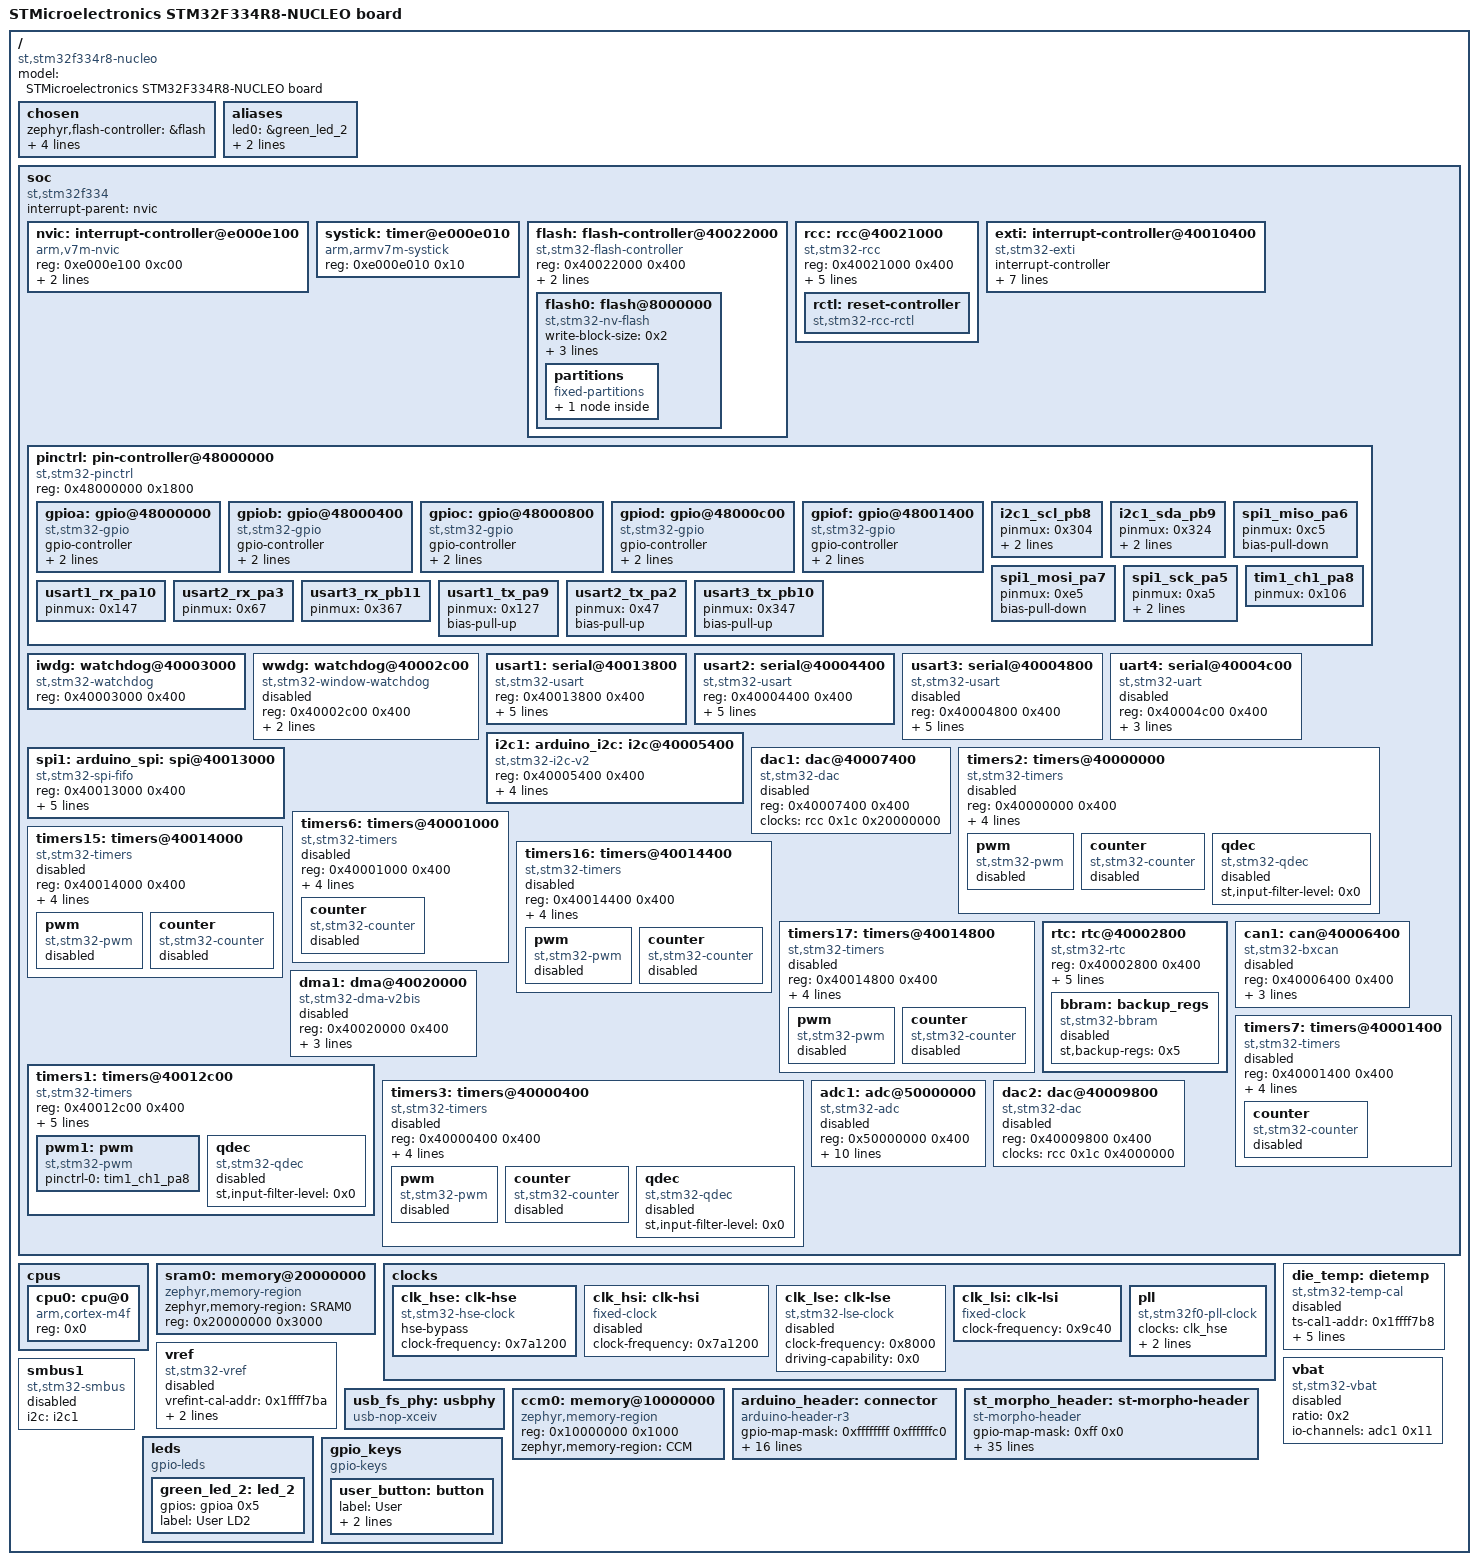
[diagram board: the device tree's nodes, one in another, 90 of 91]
/dts-v1/;

/* node '/' defined in zephyr/dts/common/skeleton.dtsi:9 */
/ {
	#address-cells = < 0x1 >;                              /* in zephyr/dts/common/skeleton.dtsi:10 */
	#size-cells = < 0x1 >;                                 /* in zephyr/dts/common/skeleton.dtsi:11 */
	model = "STMicroelectronics STM32F334R8-NUCLEO board"; /* in zephyr/boards/st/nucleo_f334r8/nucleo_f334r8.dts:15 */
	compatible = "st,stm32f334r8-nucleo";                  /* in zephyr/boards/st/nucleo_f334r8/nucleo_f334r8.dts:16 */

	/* node '/chosen' defined in zephyr/dts/common/skeleton.dtsi:13 */
	chosen {
		zephyr,flash-controller = &flash; /* in zephyr/dts/arm/st/f3/stm32f3.dtsi:24 */
		zephyr,console = &usart2;         /* in zephyr/boards/st/nucleo_f334r8/nucleo_f334r8.dts:19 */
		zephyr,shell-uart = &usart2;      /* in zephyr/boards/st/nucleo_f334r8/nucleo_f334r8.dts:20 */
		zephyr,sram = &sram0;             /* in zephyr/boards/st/nucleo_f334r8/nucleo_f334r8.dts:21 */
		zephyr,flash = &flash0;           /* in zephyr/boards/st/nucleo_f334r8/nucleo_f334r8.dts:22 */
	};

	/* node '/aliases' defined in zephyr/dts/common/skeleton.dtsi:15 */
	aliases {
		led0 = &green_led_2; /* in zephyr/boards/st/nucleo_f334r8/nucleo_f334r8.dts:45 */
		sw0 = &user_button;  /* in zephyr/boards/st/nucleo_f334r8/nucleo_f334r8.dts:46 */
		watchdog0 = &iwdg;   /* in zephyr/boards/st/nucleo_f334r8/nucleo_f334r8.dts:47 */
	};

	/* node '/soc' defined in zephyr/dts/arm/armv7-m.dtsi:6 */
	soc {
		#address-cells = < 0x1 >;     /* in zephyr/dts/arm/armv7-m.dtsi:7 */
		#size-cells = < 0x1 >;        /* in zephyr/dts/arm/armv7-m.dtsi:8 */
		interrupt-parent = < &nvic >; /* in zephyr/dts/arm/armv7-m.dtsi:10 */
		ranges;                       /* in zephyr/dts/arm/armv7-m.dtsi:11 */
		compatible = "st,stm32f334",
		             "st,stm32f3",
		             "simple-bus";    /* in zephyr/dts/arm/st/f3/stm32f334.dtsi:13 */

		/* node '/soc/interrupt-controller@e000e100' defined in zephyr/dts/arm/armv7-m.dtsi:13 */
		nvic: interrupt-controller@e000e100 {
			#address-cells = < 0x1 >;            /* in zephyr/dts/arm/armv7-m.dtsi:14 */
			compatible = "arm,v7m-nvic";         /* in zephyr/dts/arm/armv7-m.dtsi:15 */
			reg = < 0xe000e100 0xc00 >;          /* in zephyr/dts/arm/armv7-m.dtsi:16 */
			interrupt-controller;                /* in zephyr/dts/arm/armv7-m.dtsi:17 */
			#interrupt-cells = < 0x2 >;          /* in zephyr/dts/arm/armv7-m.dtsi:18 */
			arm,num-irq-priority-bits = < 0x4 >; /* in zephyr/dts/arm/st/f3/stm32f3.dtsi:456 */
			phandle = < 0x1 >;                   /* in zephyr/dts/arm/armv7-m.dtsi:10 */
		};

		/* node '/soc/timer@e000e010' defined in zephyr/dts/arm/armv7-m.dtsi:21 */
		systick: timer@e000e010 {
			compatible = "arm,armv7m-systick"; /* in zephyr/dts/arm/armv7-m.dtsi:22 */
			reg = < 0xe000e010 0x10 >;         /* in zephyr/dts/arm/armv7-m.dtsi:23 */
		};

		/* node '/soc/flash-controller@40022000' defined in zephyr/dts/arm/st/f3/stm32f3.dtsi:80 */
		flash: flash-controller@40022000 {
			compatible = "st,stm32-flash-controller",
			             "st,stm32f1-flash-controller"; /* in zephyr/dts/arm/st/f3/stm32f3.dtsi:81 */
			reg = < 0x40022000 0x400 >;                 /* in zephyr/dts/arm/st/f3/stm32f3.dtsi:82 */
			interrupts = < 0x4 0x0 >;                   /* in zephyr/dts/arm/st/f3/stm32f3.dtsi:83 */
			clocks = < &rcc 0x14 0x10 >;                /* in zephyr/dts/arm/st/f3/stm32f3.dtsi:84 */
			#address-cells = < 0x1 >;                   /* in zephyr/dts/arm/st/f3/stm32f3.dtsi:86 */
			#size-cells = < 0x1 >;                      /* in zephyr/dts/arm/st/f3/stm32f3.dtsi:87 */

			/* node '/soc/flash-controller@40022000/flash@8000000' defined in zephyr/dts/arm/st/f3/stm32f3.dtsi:89 */
			flash0: flash@8000000 {
				compatible = "st,stm32-nv-flash",
				             "soc-nv-flash";      /* in zephyr/dts/arm/st/f3/stm32f3.dtsi:90 */
				write-block-size = < 0x2 >;       /* in zephyr/dts/arm/st/f3/stm32f3.dtsi:92 */
				erase-block-size = < 0x800 >;     /* in zephyr/dts/arm/st/f3/stm32f3.dtsi:93 */
				max-erase-time = < 0x28 >;        /* in zephyr/dts/arm/st/f3/stm32f3.dtsi:95 */
				reg = < 0x8000000 0x10000 >;      /* in zephyr/dts/arm/st/f3/stm32f334X8.dtsi:23 */

				/* node '/soc/flash-controller@40022000/flash@8000000/partitions' defined in zephyr/boards/st/nucleo_f334r8/nucleo_f334r8.dts:132 */
				partitions {
					compatible = "fixed-partitions"; /* in zephyr/boards/st/nucleo_f334r8/nucleo_f334r8.dts:133 */
					#address-cells = < 0x1 >;        /* in zephyr/boards/st/nucleo_f334r8/nucleo_f334r8.dts:134 */
					#size-cells = < 0x1 >;           /* in zephyr/boards/st/nucleo_f334r8/nucleo_f334r8.dts:135 */

					/* node '/soc/flash-controller@40022000/flash@8000000/partitions/partition@e800' defined in zephyr/boards/st/nucleo_f334r8/nucleo_f334r8.dts:138 */
					storage_partition: partition@e800 {
						label = "storage";       /* in zephyr/boards/st/nucleo_f334r8/nucleo_f334r8.dts:139 */
						reg = < 0xe800 0x1800 >; /* in zephyr/boards/st/nucleo_f334r8/nucleo_f334r8.dts:140 */
					};
				};
			};
		};

		/* node '/soc/rcc@40021000' defined in zephyr/dts/arm/st/f3/stm32f3.dtsi:99 */
		rcc: rcc@40021000 {
			compatible = "st,stm32-rcc";     /* in zephyr/dts/arm/st/f3/stm32f3.dtsi:100 */
			#clock-cells = < 0x2 >;          /* in zephyr/dts/arm/st/f3/stm32f3.dtsi:101 */
			reg = < 0x40021000 0x400 >;      /* in zephyr/dts/arm/st/f3/stm32f3.dtsi:102 */
			clocks = < &pll >;               /* in zephyr/boards/st/nucleo_f334r8/nucleo_f334r8.dts:69 */
			clock-frequency = < 0x44aa200 >; /* in zephyr/boards/st/nucleo_f334r8/nucleo_f334r8.dts:70 */
			ahb-prescaler = < 0x1 >;         /* in zephyr/boards/st/nucleo_f334r8/nucleo_f334r8.dts:71 */
			apb1-prescaler = < 0x2 >;        /* in zephyr/boards/st/nucleo_f334r8/nucleo_f334r8.dts:72 */
			apb2-prescaler = < 0x1 >;        /* in zephyr/boards/st/nucleo_f334r8/nucleo_f334r8.dts:73 */
			phandle = < 0x2 >;               /* in zephyr/dts/arm/st/f3/stm32f3.dtsi:84 */

			/* node '/soc/rcc@40021000/reset-controller' defined in zephyr/dts/arm/st/f3/stm32f3.dtsi:104 */
			rctl: reset-controller {
				compatible = "st,stm32-rcc-rctl"; /* in zephyr/dts/arm/st/f3/stm32f3.dtsi:105 */
				#reset-cells = < 0x1 >;           /* in zephyr/dts/arm/st/f3/stm32f3.dtsi:106 */
				phandle = < 0x4 >;                /* in zephyr/dts/arm/st/f3/stm32f3.dtsi:191 */
			};
		};

		/* node '/soc/interrupt-controller@40010400' defined in zephyr/dts/arm/st/f3/stm32f3.dtsi:110 */
		exti: interrupt-controller@40010400 {
			compatible = "st,stm32-exti";  /* in zephyr/dts/arm/st/f3/stm32f3.dtsi:111 */
			interrupt-controller;          /* in zephyr/dts/arm/st/f3/stm32f3.dtsi:112 */
			#interrupt-cells = < 0x1 >;    /* in zephyr/dts/arm/st/f3/stm32f3.dtsi:113 */
			#address-cells = < 0x0 >;      /* in zephyr/dts/arm/st/f3/stm32f3.dtsi:114 */
			reg = < 0x40010400 0x400 >;    /* in zephyr/dts/arm/st/f3/stm32f3.dtsi:115 */
			clocks = < &rcc 0x18 0x1 >;    /* in zephyr/dts/arm/st/f3/stm32f3.dtsi:116 */
			num-lines = < 0x20 >;          /* in zephyr/dts/arm/st/f3/stm32f3.dtsi:117 */
			interrupts = < 0x6 0x0 >,
			             < 0x7 0x0 >,
			             < 0x8 0x0 >,
			             < 0x9 0x0 >,
			             < 0xa 0x0 >,
			             < 0x17 0x0 >,
			             < 0x28 0x0 >;     /* in zephyr/dts/arm/st/f3/stm32f3.dtsi:118 */
			interrupt-names = "line0",
			                  "line1",
			                  "line2",
			                  "line3",
			                  "line4",
			                  "line5-9",
			                  "line10-15"; /* in zephyr/dts/arm/st/f3/stm32f3.dtsi:120 */
			line-ranges = < 0x0 0x1 >,
			              < 0x1 0x1 >,
			              < 0x2 0x1 >,
			              < 0x3 0x1 >,
			              < 0x4 0x1 >,
			              < 0x5 0x5 >,
			              < 0xa 0x6 >;     /* in zephyr/dts/arm/st/f3/stm32f3.dtsi:122 */
		};

		/* node '/soc/pin-controller@48000000' defined in zephyr/dts/arm/st/f3/stm32f3.dtsi:126 */
		pinctrl: pin-controller@48000000 {
			compatible = "st,stm32-pinctrl"; /* in zephyr/dts/arm/st/f3/stm32f3.dtsi:127 */
			#address-cells = < 0x1 >;        /* in zephyr/dts/arm/st/f3/stm32f3.dtsi:128 */
			#size-cells = < 0x1 >;           /* in zephyr/dts/arm/st/f3/stm32f3.dtsi:129 */
			reg = < 0x48000000 0x1800 >;     /* in zephyr/dts/arm/st/f3/stm32f3.dtsi:130 */

			/* node '/soc/pin-controller@48000000/gpio@48000000' defined in zephyr/dts/arm/st/f3/stm32f3.dtsi:132 */
			gpioa: gpio@48000000 {
				compatible = "st,stm32-gpio";   /* in zephyr/dts/arm/st/f3/stm32f3.dtsi:133 */
				gpio-controller;                /* in zephyr/dts/arm/st/f3/stm32f3.dtsi:134 */
				#gpio-cells = < 0x2 >;          /* in zephyr/dts/arm/st/f3/stm32f3.dtsi:135 */
				reg = < 0x48000000 0x400 >;     /* in zephyr/dts/arm/st/f3/stm32f3.dtsi:136 */
				clocks = < &rcc 0x14 0x20000 >; /* in zephyr/dts/arm/st/f3/stm32f3.dtsi:137 */
				phandle = < 0x15 >;             /* in zephyr/boards/st/nucleo_f334r8/arduino_r3_connector.dtsi:15 */
			};

			/* node '/soc/pin-controller@48000000/gpio@48000400' defined in zephyr/dts/arm/st/f3/stm32f3.dtsi:140 */
			gpiob: gpio@48000400 {
				compatible = "st,stm32-gpio";   /* in zephyr/dts/arm/st/f3/stm32f3.dtsi:141 */
				gpio-controller;                /* in zephyr/dts/arm/st/f3/stm32f3.dtsi:142 */
				#gpio-cells = < 0x2 >;          /* in zephyr/dts/arm/st/f3/stm32f3.dtsi:143 */
				reg = < 0x48000400 0x400 >;     /* in zephyr/dts/arm/st/f3/stm32f3.dtsi:144 */
				clocks = < &rcc 0x14 0x40000 >; /* in zephyr/dts/arm/st/f3/stm32f3.dtsi:145 */
				phandle = < 0x10 >;             /* in zephyr/boards/st/nucleo_f334r8/nucleo_f334r8.dts:106 */
			};

			/* node '/soc/pin-controller@48000000/gpio@48000800' defined in zephyr/dts/arm/st/f3/stm32f3.dtsi:148 */
			gpioc: gpio@48000800 {
				compatible = "st,stm32-gpio";   /* in zephyr/dts/arm/st/f3/stm32f3.dtsi:149 */
				gpio-controller;                /* in zephyr/dts/arm/st/f3/stm32f3.dtsi:150 */
				#gpio-cells = < 0x2 >;          /* in zephyr/dts/arm/st/f3/stm32f3.dtsi:151 */
				reg = < 0x48000800 0x400 >;     /* in zephyr/dts/arm/st/f3/stm32f3.dtsi:152 */
				clocks = < &rcc 0x14 0x80000 >; /* in zephyr/dts/arm/st/f3/stm32f3.dtsi:153 */
				phandle = < 0x16 >;             /* in zephyr/boards/st/nucleo_f334r8/arduino_r3_connector.dtsi:15 */
			};

			/* node '/soc/pin-controller@48000000/gpio@48000c00' defined in zephyr/dts/arm/st/f3/stm32f3.dtsi:156 */
			gpiod: gpio@48000c00 {
				compatible = "st,stm32-gpio";    /* in zephyr/dts/arm/st/f3/stm32f3.dtsi:157 */
				gpio-controller;                 /* in zephyr/dts/arm/st/f3/stm32f3.dtsi:158 */
				#gpio-cells = < 0x2 >;           /* in zephyr/dts/arm/st/f3/stm32f3.dtsi:159 */
				reg = < 0x48000c00 0x400 >;      /* in zephyr/dts/arm/st/f3/stm32f3.dtsi:160 */
				clocks = < &rcc 0x14 0x100000 >; /* in zephyr/dts/arm/st/f3/stm32f3.dtsi:161 */
				phandle = < 0x17 >;              /* in zephyr/boards/st/nucleo_f334r8/st_morpho_connector.dtsi:15 */
			};

			/* node '/soc/pin-controller@48000000/gpio@48001400' defined in zephyr/dts/arm/st/f3/stm32f3.dtsi:164 */
			gpiof: gpio@48001400 {
				compatible = "st,stm32-gpio";    /* in zephyr/dts/arm/st/f3/stm32f3.dtsi:165 */
				gpio-controller;                 /* in zephyr/dts/arm/st/f3/stm32f3.dtsi:166 */
				#gpio-cells = < 0x2 >;           /* in zephyr/dts/arm/st/f3/stm32f3.dtsi:167 */
				reg = < 0x48001400 0x400 >;      /* in zephyr/dts/arm/st/f3/stm32f3.dtsi:168 */
				clocks = < &rcc 0x14 0x400000 >; /* in zephyr/dts/arm/st/f3/stm32f3.dtsi:169 */
				phandle = < 0x18 >;              /* in zephyr/boards/st/nucleo_f334r8/st_morpho_connector.dtsi:15 */
			};

			/* node '/soc/pin-controller@48000000/i2c1_scl_pb8' defined in modules/hal/stm32/dts/st/f3/stm32f334r(6-8)tx-pinctrl.dtsi:537 */
			i2c1_scl_pb8: i2c1_scl_pb8 {
				pinmux = < 0x304 >; /* in modules/hal/stm32/dts/st/f3/stm32f334r(6-8)tx-pinctrl.dtsi:538 */
				bias-pull-up;       /* in modules/hal/stm32/dts/st/f3/stm32f334r(6-8)tx-pinctrl.dtsi:539 */
				drive-open-drain;   /* in modules/hal/stm32/dts/st/f3/stm32f334r(6-8)tx-pinctrl.dtsi:540 */
				phandle = < 0xb >;  /* in zephyr/boards/st/nucleo_f334r8/nucleo_f334r8.dts:97 */
			};

			/* node '/soc/pin-controller@48000000/i2c1_sda_pb9' defined in modules/hal/stm32/dts/st/f3/stm32f334r(6-8)tx-pinctrl.dtsi:557 */
			i2c1_sda_pb9: i2c1_sda_pb9 {
				pinmux = < 0x324 >; /* in modules/hal/stm32/dts/st/f3/stm32f334r(6-8)tx-pinctrl.dtsi:558 */
				bias-pull-up;       /* in modules/hal/stm32/dts/st/f3/stm32f334r(6-8)tx-pinctrl.dtsi:559 */
				drive-open-drain;   /* in modules/hal/stm32/dts/st/f3/stm32f334r(6-8)tx-pinctrl.dtsi:560 */
				phandle = < 0xc >;  /* in zephyr/boards/st/nucleo_f334r8/nucleo_f334r8.dts:97 */
			};

			/* node '/soc/pin-controller@48000000/spi1_miso_pa6' defined in modules/hal/stm32/dts/st/f3/stm32f334r(6-8)tx-pinctrl.dtsi:627 */
			spi1_miso_pa6: spi1_miso_pa6 {
				pinmux = < 0xc5 >; /* in modules/hal/stm32/dts/st/f3/stm32f334r(6-8)tx-pinctrl.dtsi:628 */
				bias-pull-down;    /* in modules/hal/stm32/dts/st/f3/stm32f334r(6-8)tx-pinctrl.dtsi:629 */
				phandle = < 0xe >; /* in zephyr/boards/st/nucleo_f334r8/nucleo_f334r8.dts:104 */
			};

			/* node '/soc/pin-controller@48000000/spi1_mosi_pa7' defined in modules/hal/stm32/dts/st/f3/stm32f334r(6-8)tx-pinctrl.dtsi:639 */
			spi1_mosi_pa7: spi1_mosi_pa7 {
				pinmux = < 0xe5 >; /* in modules/hal/stm32/dts/st/f3/stm32f334r(6-8)tx-pinctrl.dtsi:640 */
				bias-pull-down;    /* in modules/hal/stm32/dts/st/f3/stm32f334r(6-8)tx-pinctrl.dtsi:641 */
				phandle = < 0xf >; /* in zephyr/boards/st/nucleo_f334r8/nucleo_f334r8.dts:104 */
			};

			/* node '/soc/pin-controller@48000000/spi1_sck_pa5' defined in modules/hal/stm32/dts/st/f3/stm32f334r(6-8)tx-pinctrl.dtsi:663 */
			spi1_sck_pa5: spi1_sck_pa5 {
				pinmux = < 0xa5 >;             /* in modules/hal/stm32/dts/st/f3/stm32f334r(6-8)tx-pinctrl.dtsi:664 */
				bias-pull-down;                /* in modules/hal/stm32/dts/st/f3/stm32f334r(6-8)tx-pinctrl.dtsi:665 */
				slew-rate = "very-high-speed"; /* in modules/hal/stm32/dts/st/f3/stm32f334r(6-8)tx-pinctrl.dtsi:666 */
				phandle = < 0xd >;             /* in zephyr/boards/st/nucleo_f334r8/nucleo_f334r8.dts:104 */
			};

			/* node '/soc/pin-controller@48000000/tim1_ch1_pa8' defined in modules/hal/stm32/dts/st/f3/stm32f334r(6-8)tx-pinctrl.dtsi:731 */
			tim1_ch1_pa8: tim1_ch1_pa8 {
				pinmux = < 0x106 >; /* in modules/hal/stm32/dts/st/f3/stm32f334r(6-8)tx-pinctrl.dtsi:732 */
				phandle = < 0x11 >; /* in zephyr/boards/st/nucleo_f334r8/nucleo_f334r8.dts:116 */
			};

			/* node '/soc/pin-controller@48000000/usart1_rx_pa10' defined in modules/hal/stm32/dts/st/f3/stm32f334r(6-8)tx-pinctrl.dtsi:1123 */
			usart1_rx_pa10: usart1_rx_pa10 {
				pinmux = < 0x147 >; /* in modules/hal/stm32/dts/st/f3/stm32f334r(6-8)tx-pinctrl.dtsi:1124 */
				phandle = < 0x6 >;  /* in zephyr/boards/st/nucleo_f334r8/nucleo_f334r8.dts:77 */
			};

			/* node '/soc/pin-controller@48000000/usart2_rx_pa3' defined in modules/hal/stm32/dts/st/f3/stm32f334r(6-8)tx-pinctrl.dtsi:1135 */
			usart2_rx_pa3: usart2_rx_pa3 {
				pinmux = < 0x67 >; /* in modules/hal/stm32/dts/st/f3/stm32f334r(6-8)tx-pinctrl.dtsi:1136 */
				phandle = < 0x8 >; /* in zephyr/boards/st/nucleo_f334r8/nucleo_f334r8.dts:84 */
			};

			/* node '/soc/pin-controller@48000000/usart3_rx_pb11' defined in modules/hal/stm32/dts/st/f3/stm32f334r(6-8)tx-pinctrl.dtsi:1151 */
			usart3_rx_pb11: usart3_rx_pb11 {
				pinmux = < 0x367 >; /* in modules/hal/stm32/dts/st/f3/stm32f334r(6-8)tx-pinctrl.dtsi:1152 */
				phandle = < 0xa >;  /* in zephyr/boards/st/nucleo_f334r8/nucleo_f334r8.dts:91 */
			};

			/* node '/soc/pin-controller@48000000/usart1_tx_pa9' defined in modules/hal/stm32/dts/st/f3/stm32f334r(6-8)tx-pinctrl.dtsi:1161 */
			usart1_tx_pa9: usart1_tx_pa9 {
				pinmux = < 0x127 >; /* in modules/hal/stm32/dts/st/f3/stm32f334r(6-8)tx-pinctrl.dtsi:1162 */
				bias-pull-up;       /* in modules/hal/stm32/dts/st/f3/stm32f334r(6-8)tx-pinctrl.dtsi:1163 */
				phandle = < 0x5 >;  /* in zephyr/boards/st/nucleo_f334r8/nucleo_f334r8.dts:77 */
			};

			/* node '/soc/pin-controller@48000000/usart2_tx_pa2' defined in modules/hal/stm32/dts/st/f3/stm32f334r(6-8)tx-pinctrl.dtsi:1176 */
			usart2_tx_pa2: usart2_tx_pa2 {
				pinmux = < 0x47 >; /* in modules/hal/stm32/dts/st/f3/stm32f334r(6-8)tx-pinctrl.dtsi:1177 */
				bias-pull-up;      /* in modules/hal/stm32/dts/st/f3/stm32f334r(6-8)tx-pinctrl.dtsi:1178 */
				phandle = < 0x7 >; /* in zephyr/boards/st/nucleo_f334r8/nucleo_f334r8.dts:84 */
			};

			/* node '/soc/pin-controller@48000000/usart3_tx_pb10' defined in modules/hal/stm32/dts/st/f3/stm32f334r(6-8)tx-pinctrl.dtsi:1196 */
			usart3_tx_pb10: usart3_tx_pb10 {
				pinmux = < 0x347 >; /* in modules/hal/stm32/dts/st/f3/stm32f334r(6-8)tx-pinctrl.dtsi:1197 */
				bias-pull-up;       /* in modules/hal/stm32/dts/st/f3/stm32f334r(6-8)tx-pinctrl.dtsi:1198 */
				phandle = < 0x9 >;  /* in zephyr/boards/st/nucleo_f334r8/nucleo_f334r8.dts:91 */
			};
		};

		/* node '/soc/watchdog@40003000' defined in zephyr/dts/arm/st/f3/stm32f3.dtsi:173 */
		iwdg: watchdog@40003000 {
			compatible = "st,stm32-watchdog"; /* in zephyr/dts/arm/st/f3/stm32f3.dtsi:174 */
			reg = < 0x40003000 0x400 >;       /* in zephyr/dts/arm/st/f3/stm32f3.dtsi:175 */
			status = "okay";                  /* in zephyr/boards/st/nucleo_f334r8/nucleo_f334r8.dts:128 */
		};

		/* node '/soc/watchdog@40002c00' defined in zephyr/dts/arm/st/f3/stm32f3.dtsi:179 */
		wwdg: watchdog@40002c00 {
			compatible = "st,stm32-window-watchdog"; /* in zephyr/dts/arm/st/f3/stm32f3.dtsi:180 */
			reg = < 0x40002c00 0x400 >;              /* in zephyr/dts/arm/st/f3/stm32f3.dtsi:181 */
			clocks = < &rcc 0x1c 0x800 >;            /* in zephyr/dts/arm/st/f3/stm32f3.dtsi:182 */
			interrupts = < 0x0 0x7 >;                /* in zephyr/dts/arm/st/f3/stm32f3.dtsi:183 */
			status = "disabled";                     /* in zephyr/dts/arm/st/f3/stm32f3.dtsi:184 */
		};

		/* node '/soc/serial@40013800' defined in zephyr/dts/arm/st/f3/stm32f3.dtsi:187 */
		usart1: serial@40013800 {
			compatible = "st,stm32-usart",
			             "st,stm32-uart";                   /* in zephyr/dts/arm/st/f3/stm32f3.dtsi:188 */
			reg = < 0x40013800 0x400 >;                     /* in zephyr/dts/arm/st/f3/stm32f3.dtsi:189 */
			clocks = < &rcc 0x18 0x4000 >;                  /* in zephyr/dts/arm/st/f3/stm32f3.dtsi:190 */
			resets = < &rctl 0x18e >;                       /* in zephyr/dts/arm/st/f3/stm32f3.dtsi:191 */
			interrupts = < 0x25 0x0 >;                      /* in zephyr/dts/arm/st/f3/stm32f3.dtsi:192 */
			pinctrl-0 = < &usart1_tx_pa9 &usart1_rx_pa10 >; /* in zephyr/boards/st/nucleo_f334r8/nucleo_f334r8.dts:77 */
			pinctrl-names = "default";                      /* in zephyr/boards/st/nucleo_f334r8/nucleo_f334r8.dts:78 */
			current-speed = < 0x1c200 >;                    /* in zephyr/boards/st/nucleo_f334r8/nucleo_f334r8.dts:79 */
			status = "okay";                                /* in zephyr/boards/st/nucleo_f334r8/nucleo_f334r8.dts:80 */
		};

		/* node '/soc/serial@40004400' defined in zephyr/dts/arm/st/f3/stm32f3.dtsi:196 */
		usart2: serial@40004400 {
			compatible = "st,stm32-usart",
			             "st,stm32-uart";                  /* in zephyr/dts/arm/st/f3/stm32f3.dtsi:197 */
			reg = < 0x40004400 0x400 >;                    /* in zephyr/dts/arm/st/f3/stm32f3.dtsi:198 */
			clocks = < &rcc 0x1c 0x20000 >;                /* in zephyr/dts/arm/st/f3/stm32f3.dtsi:199 */
			resets = < &rctl 0x211 >;                      /* in zephyr/dts/arm/st/f3/stm32f3.dtsi:200 */
			interrupts = < 0x26 0x0 >;                     /* in zephyr/dts/arm/st/f3/stm32f3.dtsi:201 */
			pinctrl-0 = < &usart2_tx_pa2 &usart2_rx_pa3 >; /* in zephyr/boards/st/nucleo_f334r8/nucleo_f334r8.dts:84 */
			pinctrl-names = "default";                     /* in zephyr/boards/st/nucleo_f334r8/nucleo_f334r8.dts:85 */
			current-speed = < 0x1c200 >;                   /* in zephyr/boards/st/nucleo_f334r8/nucleo_f334r8.dts:86 */
			status = "okay";                               /* in zephyr/boards/st/nucleo_f334r8/nucleo_f334r8.dts:87 */
		};

		/* node '/soc/serial@40004800' defined in zephyr/dts/arm/st/f3/stm32f3.dtsi:205 */
		usart3: serial@40004800 {
			compatible = "st,stm32-usart",
			             "st,stm32-uart";                    /* in zephyr/dts/arm/st/f3/stm32f3.dtsi:206 */
			reg = < 0x40004800 0x400 >;                      /* in zephyr/dts/arm/st/f3/stm32f3.dtsi:207 */
			clocks = < &rcc 0x1c 0x40000 >;                  /* in zephyr/dts/arm/st/f3/stm32f3.dtsi:208 */
			resets = < &rctl 0x212 >;                        /* in zephyr/dts/arm/st/f3/stm32f3.dtsi:209 */
			interrupts = < 0x27 0x0 >;                       /* in zephyr/dts/arm/st/f3/stm32f3.dtsi:210 */
			status = "disabled";                             /* in zephyr/dts/arm/st/f3/stm32f3.dtsi:211 */
			pinctrl-0 = < &usart3_tx_pb10 &usart3_rx_pb11 >; /* in zephyr/boards/st/nucleo_f334r8/nucleo_f334r8.dts:91 */
			pinctrl-names = "default";                       /* in zephyr/boards/st/nucleo_f334r8/nucleo_f334r8.dts:92 */
			current-speed = < 0x1c200 >;                     /* in zephyr/boards/st/nucleo_f334r8/nucleo_f334r8.dts:93 */
		};

		/* node '/soc/serial@40004c00' defined in zephyr/dts/arm/st/f3/stm32f3.dtsi:214 */
		uart4: serial@40004c00 {
			compatible = "st,stm32-uart";   /* in zephyr/dts/arm/st/f3/stm32f3.dtsi:215 */
			reg = < 0x40004c00 0x400 >;     /* in zephyr/dts/arm/st/f3/stm32f3.dtsi:216 */
			clocks = < &rcc 0x1c 0x80000 >; /* in zephyr/dts/arm/st/f3/stm32f3.dtsi:217 */
			resets = < &rctl 0x213 >;       /* in zephyr/dts/arm/st/f3/stm32f3.dtsi:218 */
			interrupts = < 0x34 0x0 >;      /* in zephyr/dts/arm/st/f3/stm32f3.dtsi:219 */
			status = "disabled";            /* in zephyr/dts/arm/st/f3/stm32f3.dtsi:220 */
		};

		/* node '/soc/i2c@40005400' defined in zephyr/dts/arm/st/f3/stm32f3.dtsi:223 */
		i2c1: arduino_i2c: i2c@40005400 {
			compatible = "st,stm32-i2c-v2";              /* in zephyr/dts/arm/st/f3/stm32f3.dtsi:224 */
			#address-cells = < 0x1 >;                    /* in zephyr/dts/arm/st/f3/stm32f3.dtsi:226 */
			#size-cells = < 0x0 >;                       /* in zephyr/dts/arm/st/f3/stm32f3.dtsi:227 */
			reg = < 0x40005400 0x400 >;                  /* in zephyr/dts/arm/st/f3/stm32f3.dtsi:228 */
			clocks = < &rcc 0x1c 0x200000 >,
			         < &rcc 0x1 0x1040030 >;             /* in zephyr/dts/arm/st/f3/stm32f3.dtsi:229 */
			interrupts = < 0x1f 0x0 >,
			             < 0x20 0x0 >;                   /* in zephyr/dts/arm/st/f3/stm32f3.dtsi:234 */
			interrupt-names = "event",
			                  "error";                   /* in zephyr/dts/arm/st/f3/stm32f3.dtsi:235 */
			pinctrl-0 = < &i2c1_scl_pb8 &i2c1_sda_pb9 >; /* in zephyr/boards/st/nucleo_f334r8/nucleo_f334r8.dts:97 */
			pinctrl-names = "default";                   /* in zephyr/boards/st/nucleo_f334r8/nucleo_f334r8.dts:98 */
			status = "okay";                             /* in zephyr/boards/st/nucleo_f334r8/nucleo_f334r8.dts:99 */
			clock-frequency = < 0x61a80 >;               /* in zephyr/boards/st/nucleo_f334r8/nucleo_f334r8.dts:100 */
			phandle = < 0x14 >;                          /* in zephyr/dts/arm/st/f3/stm32f3.dtsi:450 */
		};

		/* node '/soc/spi@40013000' defined in zephyr/dts/arm/st/f3/stm32f3.dtsi:239 */
		spi1: arduino_spi: spi@40013000 {
			compatible = "st,stm32-spi-fifo",
			             "st,stm32-spi";                                 /* in zephyr/dts/arm/st/f3/stm32f3.dtsi:240 */
			#address-cells = < 0x1 >;                                    /* in zephyr/dts/arm/st/f3/stm32f3.dtsi:241 */
			#size-cells = < 0x0 >;                                       /* in zephyr/dts/arm/st/f3/stm32f3.dtsi:242 */
			reg = < 0x40013000 0x400 >;                                  /* in zephyr/dts/arm/st/f3/stm32f3.dtsi:243 */
			clocks = < &rcc 0x18 0x1000 >;                               /* in zephyr/dts/arm/st/f3/stm32f3.dtsi:244 */
			interrupts = < 0x23 0x5 >;                                   /* in zephyr/dts/arm/st/f3/stm32f3.dtsi:245 */
			pinctrl-0 = < &spi1_sck_pa5 &spi1_miso_pa6 &spi1_mosi_pa7 >; /* in zephyr/boards/st/nucleo_f334r8/nucleo_f334r8.dts:104 */
			pinctrl-names = "default";                                   /* in zephyr/boards/st/nucleo_f334r8/nucleo_f334r8.dts:105 */
			cs-gpios = < &gpiob 0x6 0x11 >;                              /* in zephyr/boards/st/nucleo_f334r8/nucleo_f334r8.dts:106 */
			status = "okay";                                             /* in zephyr/boards/st/nucleo_f334r8/nucleo_f334r8.dts:107 */
		};

		/* node '/soc/dac@40007400' defined in zephyr/dts/arm/st/f3/stm32f3.dtsi:249 */
		dac1: dac@40007400 {
			compatible = "st,stm32-dac";       /* in zephyr/dts/arm/st/f3/stm32f3.dtsi:250 */
			reg = < 0x40007400 0x400 >;        /* in zephyr/dts/arm/st/f3/stm32f3.dtsi:251 */
			clocks = < &rcc 0x1c 0x20000000 >; /* in zephyr/dts/arm/st/f3/stm32f3.dtsi:252 */
			status = "disabled";               /* in zephyr/dts/arm/st/f3/stm32f3.dtsi:253 */
			#io-channel-cells = < 0x1 >;       /* in zephyr/dts/arm/st/f3/stm32f3.dtsi:254 */
		};

		/* node '/soc/timers@40000000' defined in zephyr/dts/arm/st/f3/stm32f3.dtsi:270 */
		timers2: timers@40000000 {
			compatible = "st,stm32-timers"; /* in zephyr/dts/arm/st/f3/stm32f3.dtsi:271 */
			reg = < 0x40000000 0x400 >;     /* in zephyr/dts/arm/st/f3/stm32f3.dtsi:272 */
			clocks = < &rcc 0x1c 0x1 >,
			         < &rcc 0x6 0xff >;     /* in zephyr/dts/arm/st/f3/stm32f3.dtsi:273 */
			resets = < &rctl 0x200 >;       /* in zephyr/dts/arm/st/f3/stm32f3.dtsi:275 */
			interrupts = < 0x1c 0x0 >;      /* in zephyr/dts/arm/st/f3/stm32f3.dtsi:276 */
			interrupt-names = "global";     /* in zephyr/dts/arm/st/f3/stm32f3.dtsi:277 */
			st,prescaler = < 0x0 >;         /* in zephyr/dts/arm/st/f3/stm32f3.dtsi:278 */
			status = "disabled";            /* in zephyr/dts/arm/st/f3/stm32f3.dtsi:279 */

			/* node '/soc/timers@40000000/pwm' defined in zephyr/dts/arm/st/f3/stm32f3.dtsi:281 */
			pwm {
				compatible = "st,stm32-pwm"; /* in zephyr/dts/arm/st/f3/stm32f3.dtsi:282 */
				status = "disabled";         /* in zephyr/dts/arm/st/f3/stm32f3.dtsi:283 */
				#pwm-cells = < 0x3 >;        /* in zephyr/dts/arm/st/f3/stm32f3.dtsi:284 */
			};

			/* node '/soc/timers@40000000/counter' defined in zephyr/dts/arm/st/f3/stm32f3.dtsi:287 */
			counter {
				compatible = "st,stm32-counter"; /* in zephyr/dts/arm/st/f3/stm32f3.dtsi:288 */
				status = "disabled";             /* in zephyr/dts/arm/st/f3/stm32f3.dtsi:289 */
			};

			/* node '/soc/timers@40000000/qdec' defined in zephyr/dts/arm/st/f3/stm32f3.dtsi:292 */
			qdec {
				compatible = "st,stm32-qdec";    /* in zephyr/dts/arm/st/f3/stm32f3.dtsi:293 */
				st,input-filter-level = < 0x0 >; /* in zephyr/dts/arm/st/f3/stm32f3.dtsi:294 */
				status = "disabled";             /* in zephyr/dts/arm/st/f3/stm32f3.dtsi:295 */
			};
		};

		/* node '/soc/timers@40001000' defined in zephyr/dts/arm/st/f3/stm32f3.dtsi:299 */
		timers6: timers@40001000 {
			compatible = "st,stm32-timers"; /* in zephyr/dts/arm/st/f3/stm32f3.dtsi:300 */
			reg = < 0x40001000 0x400 >;     /* in zephyr/dts/arm/st/f3/stm32f3.dtsi:301 */
			clocks = < &rcc 0x1c 0x10 >,
			         < &rcc 0x6 0xff >;     /* in zephyr/dts/arm/st/f3/stm32f3.dtsi:302 */
			resets = < &rctl 0x204 >;       /* in zephyr/dts/arm/st/f3/stm32f3.dtsi:304 */
			interrupts = < 0x36 0x0 >;      /* in zephyr/dts/arm/st/f3/stm32f3.dtsi:305 */
			interrupt-names = "global";     /* in zephyr/dts/arm/st/f3/stm32f3.dtsi:306 */
			st,prescaler = < 0x0 >;         /* in zephyr/dts/arm/st/f3/stm32f3.dtsi:307 */
			status = "disabled";            /* in zephyr/dts/arm/st/f3/stm32f3.dtsi:308 */

			/* node '/soc/timers@40001000/counter' defined in zephyr/dts/arm/st/f3/stm32f3.dtsi:310 */
			counter {
				compatible = "st,stm32-counter"; /* in zephyr/dts/arm/st/f3/stm32f3.dtsi:311 */
				status = "disabled";             /* in zephyr/dts/arm/st/f3/stm32f3.dtsi:312 */
			};
		};

		/* node '/soc/timers@40014000' defined in zephyr/dts/arm/st/f3/stm32f3.dtsi:316 */
		timers15: timers@40014000 {
			compatible = "st,stm32-timers"; /* in zephyr/dts/arm/st/f3/stm32f3.dtsi:317 */
			reg = < 0x40014000 0x400 >;     /* in zephyr/dts/arm/st/f3/stm32f3.dtsi:318 */
			clocks = < &rcc 0x18 0x10000 >,
			         < &rcc 0x7 0xff >;     /* in zephyr/dts/arm/st/f3/stm32f3.dtsi:319 */
			resets = < &rctl 0x190 >;       /* in zephyr/dts/arm/st/f3/stm32f3.dtsi:321 */
			interrupts = < 0x18 0x0 >;      /* in zephyr/dts/arm/st/f3/stm32f3.dtsi:322 */
			interrupt-names = "global";     /* in zephyr/dts/arm/st/f3/stm32f3.dtsi:323 */
			st,prescaler = < 0x0 >;         /* in zephyr/dts/arm/st/f3/stm32f3.dtsi:324 */
			status = "disabled";            /* in zephyr/dts/arm/st/f3/stm32f3.dtsi:325 */

			/* node '/soc/timers@40014000/pwm' defined in zephyr/dts/arm/st/f3/stm32f3.dtsi:327 */
			pwm {
				compatible = "st,stm32-pwm"; /* in zephyr/dts/arm/st/f3/stm32f3.dtsi:328 */
				status = "disabled";         /* in zephyr/dts/arm/st/f3/stm32f3.dtsi:329 */
				#pwm-cells = < 0x3 >;        /* in zephyr/dts/arm/st/f3/stm32f3.dtsi:330 */
			};

			/* node '/soc/timers@40014000/counter' defined in zephyr/dts/arm/st/f3/stm32f3.dtsi:333 */
			counter {
				compatible = "st,stm32-counter"; /* in zephyr/dts/arm/st/f3/stm32f3.dtsi:334 */
				status = "disabled";             /* in zephyr/dts/arm/st/f3/stm32f3.dtsi:335 */
			};
		};

		/* node '/soc/timers@40014400' defined in zephyr/dts/arm/st/f3/stm32f3.dtsi:339 */
		timers16: timers@40014400 {
			compatible = "st,stm32-timers"; /* in zephyr/dts/arm/st/f3/stm32f3.dtsi:340 */
			reg = < 0x40014400 0x400 >;     /* in zephyr/dts/arm/st/f3/stm32f3.dtsi:341 */
			clocks = < &rcc 0x18 0x20000 >,
			         < &rcc 0x7 0xff >;     /* in zephyr/dts/arm/st/f3/stm32f3.dtsi:342 */
			resets = < &rctl 0x191 >;       /* in zephyr/dts/arm/st/f3/stm32f3.dtsi:344 */
			interrupts = < 0x19 0x0 >;      /* in zephyr/dts/arm/st/f3/stm32f3.dtsi:345 */
			interrupt-names = "global";     /* in zephyr/dts/arm/st/f3/stm32f3.dtsi:346 */
			st,prescaler = < 0x0 >;         /* in zephyr/dts/arm/st/f3/stm32f3.dtsi:347 */
			status = "disabled";            /* in zephyr/dts/arm/st/f3/stm32f3.dtsi:348 */

			/* node '/soc/timers@40014400/pwm' defined in zephyr/dts/arm/st/f3/stm32f3.dtsi:350 */
			pwm {
				compatible = "st,stm32-pwm"; /* in zephyr/dts/arm/st/f3/stm32f3.dtsi:351 */
				status = "disabled";         /* in zephyr/dts/arm/st/f3/stm32f3.dtsi:352 */
				#pwm-cells = < 0x3 >;        /* in zephyr/dts/arm/st/f3/stm32f3.dtsi:353 */
			};

			/* node '/soc/timers@40014400/counter' defined in zephyr/dts/arm/st/f3/stm32f3.dtsi:356 */
			counter {
				compatible = "st,stm32-counter"; /* in zephyr/dts/arm/st/f3/stm32f3.dtsi:357 */
				status = "disabled";             /* in zephyr/dts/arm/st/f3/stm32f3.dtsi:358 */
			};
		};

		/* node '/soc/timers@40014800' defined in zephyr/dts/arm/st/f3/stm32f3.dtsi:362 */
		timers17: timers@40014800 {
			compatible = "st,stm32-timers"; /* in zephyr/dts/arm/st/f3/stm32f3.dtsi:363 */
			reg = < 0x40014800 0x400 >;     /* in zephyr/dts/arm/st/f3/stm32f3.dtsi:364 */
			clocks = < &rcc 0x18 0x40000 >,
			         < &rcc 0x7 0xff >;     /* in zephyr/dts/arm/st/f3/stm32f3.dtsi:365 */
			resets = < &rctl 0x192 >;       /* in zephyr/dts/arm/st/f3/stm32f3.dtsi:367 */
			interrupts = < 0x1a 0x0 >;      /* in zephyr/dts/arm/st/f3/stm32f3.dtsi:368 */
			interrupt-names = "global";     /* in zephyr/dts/arm/st/f3/stm32f3.dtsi:369 */
			st,prescaler = < 0x0 >;         /* in zephyr/dts/arm/st/f3/stm32f3.dtsi:370 */
			status = "disabled";            /* in zephyr/dts/arm/st/f3/stm32f3.dtsi:371 */

			/* node '/soc/timers@40014800/pwm' defined in zephyr/dts/arm/st/f3/stm32f3.dtsi:373 */
			pwm {
				compatible = "st,stm32-pwm"; /* in zephyr/dts/arm/st/f3/stm32f3.dtsi:374 */
				status = "disabled";         /* in zephyr/dts/arm/st/f3/stm32f3.dtsi:375 */
				#pwm-cells = < 0x3 >;        /* in zephyr/dts/arm/st/f3/stm32f3.dtsi:376 */
			};

			/* node '/soc/timers@40014800/counter' defined in zephyr/dts/arm/st/f3/stm32f3.dtsi:379 */
			counter {
				compatible = "st,stm32-counter"; /* in zephyr/dts/arm/st/f3/stm32f3.dtsi:380 */
				status = "disabled";             /* in zephyr/dts/arm/st/f3/stm32f3.dtsi:381 */
			};
		};

		/* node '/soc/rtc@40002800' defined in zephyr/dts/arm/st/f3/stm32f3.dtsi:385 */
		rtc: rtc@40002800 {
			compatible = "st,stm32-rtc";       /* in zephyr/dts/arm/st/f3/stm32f3.dtsi:386 */
			reg = < 0x40002800 0x400 >;        /* in zephyr/dts/arm/st/f3/stm32f3.dtsi:387 */
			interrupts = < 0x29 0x0 >;         /* in zephyr/dts/arm/st/f3/stm32f3.dtsi:389 */
			prescaler = < 0x8000 >;            /* in zephyr/dts/arm/st/f3/stm32f3.dtsi:390 */
			alarms-count = < 0x2 >;            /* in zephyr/dts/arm/st/f3/stm32f3.dtsi:391 */
			alrm-exti-line = < 0x11 >;         /* in zephyr/dts/arm/st/f3/stm32f3.dtsi:392 */
			clocks = < &rcc 0x1c 0x10000000 >,
			         < &rcc 0x3 0x2280020 >;   /* in zephyr/boards/st/nucleo_f334r8/nucleo_f334r8.dts:122 */
			status = "okay";                   /* in zephyr/boards/st/nucleo_f334r8/nucleo_f334r8.dts:124 */

			/* node '/soc/rtc@40002800/backup_regs' defined in zephyr/dts/arm/st/f3/stm32f334.dtsi:105 */
			bbram: backup_regs {
				compatible = "st,stm32-bbram"; /* in zephyr/dts/arm/st/f3/stm32f334.dtsi:106 */
				st,backup-regs = < 0x5 >;      /* in zephyr/dts/arm/st/f3/stm32f334.dtsi:107 */
				status = "disabled";           /* in zephyr/dts/arm/st/f3/stm32f334.dtsi:108 */
			};
		};

		/* node '/soc/can@40006400' defined in zephyr/dts/arm/st/f3/stm32f3.dtsi:396 */
		can1: can@40006400 {
			compatible = "st,stm32-bxcan";    /* in zephyr/dts/arm/st/f3/stm32f3.dtsi:397 */
			reg = < 0x40006400 0x400 >;       /* in zephyr/dts/arm/st/f3/stm32f3.dtsi:398 */
			interrupts = < 0x13 0x0 >,
			             < 0x14 0x0 >,
			             < 0x15 0x0 >,
			             < 0x16 0x0 >;        /* in zephyr/dts/arm/st/f3/stm32f3.dtsi:399 */
			interrupt-names = "TX",
			                  "RX0",
			                  "RX1",
			                  "SCE";          /* in zephyr/dts/arm/st/f3/stm32f3.dtsi:400 */
			clocks = < &rcc 0x1c 0x2000000 >; /* in zephyr/dts/arm/st/f3/stm32f3.dtsi:401 */
			status = "disabled";              /* in zephyr/dts/arm/st/f3/stm32f3.dtsi:402 */
		};

		/* node '/soc/dma@40020000' defined in zephyr/dts/arm/st/f3/stm32f3.dtsi:405 */
		dma1: dma@40020000 {
			compatible = "st,stm32-dma-v2bis";                                          /* in zephyr/dts/arm/st/f3/stm32f3.dtsi:406 */
			#dma-cells = < 0x2 >;                                                       /* in zephyr/dts/arm/st/f3/stm32f3.dtsi:407 */
			reg = < 0x40020000 0x400 >;                                                 /* in zephyr/dts/arm/st/f3/stm32f3.dtsi:408 */
			clocks = < &rcc 0x14 0x1 >;                                                 /* in zephyr/dts/arm/st/f3/stm32f3.dtsi:409 */
			interrupts = < 0xb 0x0 0xc 0x0 0xd 0x0 0xe 0x0 0xf 0x0 0x10 0x0 0x11 0x0 >; /* in zephyr/dts/arm/st/f3/stm32f3.dtsi:410 */
			status = "disabled";                                                        /* in zephyr/dts/arm/st/f3/stm32f3.dtsi:411 */
		};

		/* node '/soc/timers@40012c00' defined in zephyr/dts/arm/st/f3/stm32f334.dtsi:15 */
		timers1: timers@40012c00 {
			compatible = "st,stm32-timers"; /* in zephyr/dts/arm/st/f3/stm32f334.dtsi:16 */
			reg = < 0x40012c00 0x400 >;     /* in zephyr/dts/arm/st/f3/stm32f334.dtsi:17 */
			clocks = < &rcc 0x18 0x800 >,
			         < &rcc 0x7 0x80030 >;  /* in zephyr/dts/arm/st/f3/stm32f334.dtsi:18 */
			resets = < &rctl 0x18b >;       /* in zephyr/dts/arm/st/f3/stm32f334.dtsi:20 */
			interrupts = < 0x18 0x0 >,
			             < 0x19 0x0 >,
			             < 0x1a 0x0 >,
			             < 0x1b 0x0 >;      /* in zephyr/dts/arm/st/f3/stm32f334.dtsi:21 */
			interrupt-names = "brk",
			                  "up",
			                  "trgcom",
			                  "cc";         /* in zephyr/dts/arm/st/f3/stm32f334.dtsi:22 */
			st,prescaler = < 0x2710 >;      /* in zephyr/boards/st/nucleo_f334r8/nucleo_f334r8.dts:111 */
			status = "okay";                /* in zephyr/boards/st/nucleo_f334r8/nucleo_f334r8.dts:112 */

			/* node '/soc/timers@40012c00/pwm' defined in zephyr/dts/arm/st/f3/stm32f334.dtsi:26 */
			pwm1: pwm {
				compatible = "st,stm32-pwm";   /* in zephyr/dts/arm/st/f3/stm32f334.dtsi:27 */
				#pwm-cells = < 0x3 >;          /* in zephyr/dts/arm/st/f3/stm32f334.dtsi:29 */
				status = "okay";               /* in zephyr/boards/st/nucleo_f334r8/nucleo_f334r8.dts:115 */
				pinctrl-0 = < &tim1_ch1_pa8 >; /* in zephyr/boards/st/nucleo_f334r8/nucleo_f334r8.dts:116 */
				pinctrl-names = "default";     /* in zephyr/boards/st/nucleo_f334r8/nucleo_f334r8.dts:117 */
			};

			/* node '/soc/timers@40012c00/qdec' defined in zephyr/dts/arm/st/f3/stm32f334.dtsi:32 */
			qdec {
				compatible = "st,stm32-qdec";    /* in zephyr/dts/arm/st/f3/stm32f334.dtsi:33 */
				st,input-filter-level = < 0x0 >; /* in zephyr/dts/arm/st/f3/stm32f334.dtsi:34 */
				status = "disabled";             /* in zephyr/dts/arm/st/f3/stm32f334.dtsi:35 */
			};
		};

		/* node '/soc/timers@40000400' defined in zephyr/dts/arm/st/f3/stm32f334.dtsi:39 */
		timers3: timers@40000400 {
			compatible = "st,stm32-timers"; /* in zephyr/dts/arm/st/f3/stm32f334.dtsi:40 */
			reg = < 0x40000400 0x400 >;     /* in zephyr/dts/arm/st/f3/stm32f334.dtsi:41 */
			clocks = < &rcc 0x1c 0x2 >,
			         < &rcc 0x6 0xff >;     /* in zephyr/dts/arm/st/f3/stm32f334.dtsi:42 */
			resets = < &rctl 0x201 >;       /* in zephyr/dts/arm/st/f3/stm32f334.dtsi:44 */
			interrupts = < 0x1d 0x0 >;      /* in zephyr/dts/arm/st/f3/stm32f334.dtsi:45 */
			interrupt-names = "global";     /* in zephyr/dts/arm/st/f3/stm32f334.dtsi:46 */
			st,prescaler = < 0x0 >;         /* in zephyr/dts/arm/st/f3/stm32f334.dtsi:47 */
			status = "disabled";            /* in zephyr/dts/arm/st/f3/stm32f334.dtsi:48 */

			/* node '/soc/timers@40000400/pwm' defined in zephyr/dts/arm/st/f3/stm32f334.dtsi:50 */
			pwm {
				compatible = "st,stm32-pwm"; /* in zephyr/dts/arm/st/f3/stm32f334.dtsi:51 */
				status = "disabled";         /* in zephyr/dts/arm/st/f3/stm32f334.dtsi:52 */
				#pwm-cells = < 0x3 >;        /* in zephyr/dts/arm/st/f3/stm32f334.dtsi:53 */
			};

			/* node '/soc/timers@40000400/counter' defined in zephyr/dts/arm/st/f3/stm32f334.dtsi:56 */
			counter {
				compatible = "st,stm32-counter"; /* in zephyr/dts/arm/st/f3/stm32f334.dtsi:57 */
				status = "disabled";             /* in zephyr/dts/arm/st/f3/stm32f334.dtsi:58 */
			};

			/* node '/soc/timers@40000400/qdec' defined in zephyr/dts/arm/st/f3/stm32f334.dtsi:61 */
			qdec {
				compatible = "st,stm32-qdec";    /* in zephyr/dts/arm/st/f3/stm32f334.dtsi:62 */
				st,input-filter-level = < 0x0 >; /* in zephyr/dts/arm/st/f3/stm32f334.dtsi:63 */
				status = "disabled";             /* in zephyr/dts/arm/st/f3/stm32f334.dtsi:64 */
			};
		};

		/* node '/soc/timers@40001400' defined in zephyr/dts/arm/st/f3/stm32f334.dtsi:68 */
		timers7: timers@40001400 {
			compatible = "st,stm32-timers"; /* in zephyr/dts/arm/st/f3/stm32f334.dtsi:69 */
			reg = < 0x40001400 0x400 >;     /* in zephyr/dts/arm/st/f3/stm32f334.dtsi:70 */
			clocks = < &rcc 0x1c 0x20 >,
			         < &rcc 0x6 0xff >;     /* in zephyr/dts/arm/st/f3/stm32f334.dtsi:71 */
			resets = < &rctl 0x205 >;       /* in zephyr/dts/arm/st/f3/stm32f334.dtsi:73 */
			interrupts = < 0x37 0x0 >;      /* in zephyr/dts/arm/st/f3/stm32f334.dtsi:74 */
			interrupt-names = "global";     /* in zephyr/dts/arm/st/f3/stm32f334.dtsi:75 */
			st,prescaler = < 0x0 >;         /* in zephyr/dts/arm/st/f3/stm32f334.dtsi:76 */
			status = "disabled";            /* in zephyr/dts/arm/st/f3/stm32f334.dtsi:77 */

			/* node '/soc/timers@40001400/counter' defined in zephyr/dts/arm/st/f3/stm32f334.dtsi:79 */
			counter {
				compatible = "st,stm32-counter"; /* in zephyr/dts/arm/st/f3/stm32f334.dtsi:80 */
				status = "disabled";             /* in zephyr/dts/arm/st/f3/stm32f334.dtsi:81 */
			};
		};

		/* node '/soc/adc@50000000' defined in zephyr/dts/arm/st/f3/stm32f334.dtsi:85 */
		adc1: adc@50000000 {
			compatible = "st,stm32-adc";                               /* in zephyr/dts/arm/st/f3/stm32f334.dtsi:86 */
			reg = < 0x50000000 0x400 >;                                /* in zephyr/dts/arm/st/f3/stm32f334.dtsi:87 */
			clocks = < &rcc 0x14 0x10000000 >;                         /* in zephyr/dts/arm/st/f3/stm32f334.dtsi:88 */
			clock-names = "adcx";                                      /* in zephyr/dts/arm/st/f3/stm32f334.dtsi:89 */
			interrupts = < 0x12 0x0 >;                                 /* in zephyr/dts/arm/st/f3/stm32f334.dtsi:90 */
			#io-channel-cells = < 0x1 >;                               /* in zephyr/dts/arm/st/f3/stm32f334.dtsi:91 */
			resolutions = < 0x60630c 0x51630c 0x42630c 0x33630c >;     /* in zephyr/dts/arm/st/f3/stm32f334.dtsi:92 */
			sampling-times = < 0x2 0x3 0x5 0x8 0x14 0x3e 0xb6 0x25a >; /* in zephyr/dts/arm/st/f3/stm32f334.dtsi:96 */
			st,adc-sequencer = "programmable";                         /* in zephyr/dts/arm/st/f3/stm32f334.dtsi:97 */
			st,adc-oversampler = "none";                               /* in zephyr/dts/arm/st/f3/stm32f334.dtsi:98 */
			st,adc-internal-regulator = "startup-sw-delay";            /* in zephyr/dts/arm/st/f3/stm32f334.dtsi:99 */
			st,adc-has-differential-support;                           /* in zephyr/dts/arm/st/f3/stm32f334.dtsi:100 */
			status = "disabled";                                       /* in zephyr/dts/arm/st/f3/stm32f334.dtsi:101 */
			phandle = < 0x13 >;                                        /* in zephyr/dts/arm/st/f3/stm32f3.dtsi:422 */
		};

		/* node '/soc/dac@40009800' defined in zephyr/dts/arm/st/f3/stm32f334X8.dtsi:27 */
		dac2: dac@40009800 {
			compatible = "st,stm32-dac";      /* in zephyr/dts/arm/st/f3/stm32f334X8.dtsi:28 */
			reg = < 0x40009800 0x400 >;       /* in zephyr/dts/arm/st/f3/stm32f334X8.dtsi:29 */
			clocks = < &rcc 0x1c 0x4000000 >; /* in zephyr/dts/arm/st/f3/stm32f334X8.dtsi:30 */
			status = "disabled";              /* in zephyr/dts/arm/st/f3/stm32f334X8.dtsi:31 */
			#io-channel-cells = < 0x1 >;      /* in zephyr/dts/arm/st/f3/stm32f334X8.dtsi:32 */
		};
	};

	/* node '/cpus' defined in zephyr/dts/arm/st/f3/stm32f3.dtsi:27 */
	cpus {
		#address-cells = < 0x1 >; /* in zephyr/dts/arm/st/f3/stm32f3.dtsi:28 */
		#size-cells = < 0x0 >;    /* in zephyr/dts/arm/st/f3/stm32f3.dtsi:29 */

		/* node '/cpus/cpu@0' defined in zephyr/dts/arm/st/f3/stm32f3.dtsi:31 */
		cpu0: cpu@0 {
			device_type = "cpu";           /* in zephyr/dts/arm/st/f3/stm32f3.dtsi:32 */
			compatible = "arm,cortex-m4f"; /* in zephyr/dts/arm/st/f3/stm32f3.dtsi:33 */
			reg = < 0x0 >;                 /* in zephyr/dts/arm/st/f3/stm32f3.dtsi:34 */
		};
	};

	/* node '/memory@20000000' defined in zephyr/dts/arm/st/f3/stm32f3.dtsi:38 */
	sram0: memory@20000000 {
		compatible = "zephyr,memory-region",
		             "mmio-sram";            /* in zephyr/dts/arm/st/f3/stm32f3.dtsi:39 */
		zephyr,memory-region = "SRAM0";      /* in zephyr/dts/arm/st/f3/stm32f3.dtsi:40 */
		reg = < 0x20000000 0x3000 >;         /* in zephyr/dts/arm/st/f3/stm32f334X8.dtsi:17 */
	};

	/* node '/clocks' defined in zephyr/dts/arm/st/f3/stm32f3.dtsi:43 */
	clocks {

		/* node '/clocks/clk-hse' defined in zephyr/dts/arm/st/f3/stm32f3.dtsi:44 */
		clk_hse: clk-hse {
			#clock-cells = < 0x0 >;            /* in zephyr/dts/arm/st/f3/stm32f3.dtsi:45 */
			compatible = "st,stm32-hse-clock"; /* in zephyr/dts/arm/st/f3/stm32f3.dtsi:46 */
			hse-bypass;                        /* in zephyr/boards/st/nucleo_f334r8/nucleo_f334r8.dts:56 */
			clock-frequency = < 0x7a1200 >;    /* in zephyr/boards/st/nucleo_f334r8/nucleo_f334r8.dts:57 */
			status = "okay";                   /* in zephyr/boards/st/nucleo_f334r8/nucleo_f334r8.dts:58 */
			phandle = < 0x12 >;                /* in zephyr/boards/st/nucleo_f334r8/nucleo_f334r8.dts:62 */
		};

		/* node '/clocks/clk-hsi' defined in zephyr/dts/arm/st/f3/stm32f3.dtsi:50 */
		clk_hsi: clk-hsi {
			#clock-cells = < 0x0 >;         /* in zephyr/dts/arm/st/f3/stm32f3.dtsi:51 */
			compatible = "fixed-clock";     /* in zephyr/dts/arm/st/f3/stm32f3.dtsi:52 */
			clock-frequency = < 0x7a1200 >; /* in zephyr/dts/arm/st/f3/stm32f3.dtsi:53 */
			status = "disabled";            /* in zephyr/dts/arm/st/f3/stm32f3.dtsi:54 */
		};

		/* node '/clocks/clk-lse' defined in zephyr/dts/arm/st/f3/stm32f3.dtsi:57 */
		clk_lse: clk-lse {
			#clock-cells = < 0x0 >;            /* in zephyr/dts/arm/st/f3/stm32f3.dtsi:58 */
			compatible = "st,stm32-lse-clock"; /* in zephyr/dts/arm/st/f3/stm32f3.dtsi:59 */
			clock-frequency = < 0x8000 >;      /* in zephyr/dts/arm/st/f3/stm32f3.dtsi:60 */
			driving-capability = < 0x0 >;      /* in zephyr/dts/arm/st/f3/stm32f3.dtsi:61 */
			status = "disabled";               /* in zephyr/dts/arm/st/f3/stm32f3.dtsi:62 */
		};

		/* node '/clocks/clk-lsi' defined in zephyr/dts/arm/st/f3/stm32f3.dtsi:65 */
		clk_lsi: clk-lsi {
			#clock-cells = < 0x0 >;       /* in zephyr/dts/arm/st/f3/stm32f3.dtsi:66 */
			compatible = "fixed-clock";   /* in zephyr/dts/arm/st/f3/stm32f3.dtsi:67 */
			clock-frequency = < 0x9c40 >; /* in zephyr/dts/arm/st/f3/stm32f3.dtsi:68 */
			status = "okay";              /* in zephyr/boards/st/nucleo_f334r8/nucleo_f334r8.dts:52 */
		};

		/* node '/clocks/pll' defined in zephyr/dts/arm/st/f3/stm32f3.dtsi:72 */
		pll: pll {
			#clock-cells = < 0x0 >;              /* in zephyr/dts/arm/st/f3/stm32f3.dtsi:73 */
			compatible = "st,stm32f0-pll-clock"; /* in zephyr/dts/arm/st/f3/stm32f3.dtsi:74 */
			clocks = < &clk_hse >;               /* in zephyr/boards/st/nucleo_f334r8/nucleo_f334r8.dts:62 */
			prediv = < 0x1 >;                    /* in zephyr/boards/st/nucleo_f334r8/nucleo_f334r8.dts:63 */
			mul = < 0x9 >;                       /* in zephyr/boards/st/nucleo_f334r8/nucleo_f334r8.dts:64 */
			status = "okay";                     /* in zephyr/boards/st/nucleo_f334r8/nucleo_f334r8.dts:65 */
			phandle = < 0x3 >;                   /* in zephyr/boards/st/nucleo_f334r8/nucleo_f334r8.dts:69 */
		};
	};

	/* node '/dietemp' defined in zephyr/dts/arm/st/f3/stm32f3.dtsi:415 */
	die_temp: dietemp {
		compatible = "st,stm32-temp-cal"; /* in zephyr/dts/arm/st/f3/stm32f3.dtsi:416 */
		ts-cal1-addr = < 0x1ffff7b8 >;    /* in zephyr/dts/arm/st/f3/stm32f3.dtsi:417 */
		ts-cal2-addr = < 0x1ffff7c2 >;    /* in zephyr/dts/arm/st/f3/stm32f3.dtsi:418 */
		ts-cal1-temp = < 0x1e >;          /* in zephyr/dts/arm/st/f3/stm32f3.dtsi:419 */
		ts-cal2-temp = < 0x6e >;          /* in zephyr/dts/arm/st/f3/stm32f3.dtsi:420 */
		ts-cal-vrefanalog = < 0xce4 >;    /* in zephyr/dts/arm/st/f3/stm32f3.dtsi:421 */
		io-channels = < &adc1 0x10 >;     /* in zephyr/dts/arm/st/f3/stm32f3.dtsi:422 */
		status = "disabled";              /* in zephyr/dts/arm/st/f3/stm32f3.dtsi:423 */
	};

	/* node '/vref' defined in zephyr/dts/arm/st/f3/stm32f3.dtsi:426 */
	vref: vref {
		compatible = "st,stm32-vref";      /* in zephyr/dts/arm/st/f3/stm32f3.dtsi:427 */
		vrefint-cal-addr = < 0x1ffff7ba >; /* in zephyr/dts/arm/st/f3/stm32f3.dtsi:428 */
		vrefint-cal-mv = < 0xce4 >;        /* in zephyr/dts/arm/st/f3/stm32f3.dtsi:429 */
		io-channels = < &adc1 0x12 >;      /* in zephyr/dts/arm/st/f3/stm32f3.dtsi:430 */
		status = "disabled";               /* in zephyr/dts/arm/st/f3/stm32f3.dtsi:431 */
	};

	/* node '/vbat' defined in zephyr/dts/arm/st/f3/stm32f3.dtsi:434 */
	vbat: vbat {
		compatible = "st,stm32-vbat"; /* in zephyr/dts/arm/st/f3/stm32f3.dtsi:435 */
		ratio = < 0x2 >;              /* in zephyr/dts/arm/st/f3/stm32f3.dtsi:436 */
		io-channels = < &adc1 0x11 >; /* in zephyr/dts/arm/st/f3/stm32f3.dtsi:437 */
		status = "disabled";          /* in zephyr/dts/arm/st/f3/stm32f3.dtsi:438 */
	};

	/* node '/usbphy' defined in zephyr/dts/arm/st/f3/stm32f3.dtsi:441 */
	usb_fs_phy: usbphy {
		compatible = "usb-nop-xceiv"; /* in zephyr/dts/arm/st/f3/stm32f3.dtsi:442 */
		#phy-cells = < 0x0 >;         /* in zephyr/dts/arm/st/f3/stm32f3.dtsi:443 */
	};

	/* node '/smbus1' defined in zephyr/dts/arm/st/f3/stm32f3.dtsi:446 */
	smbus1: smbus1 {
		compatible = "st,stm32-smbus"; /* in zephyr/dts/arm/st/f3/stm32f3.dtsi:447 */
		#address-cells = < 0x1 >;      /* in zephyr/dts/arm/st/f3/stm32f3.dtsi:448 */
		#size-cells = < 0x0 >;         /* in zephyr/dts/arm/st/f3/stm32f3.dtsi:449 */
		i2c = < &i2c1 >;               /* in zephyr/dts/arm/st/f3/stm32f3.dtsi:450 */
		status = "disabled";           /* in zephyr/dts/arm/st/f3/stm32f3.dtsi:451 */
	};

	/* node '/memory@10000000' defined in zephyr/dts/arm/st/f3/stm32f334X8.dtsi:10 */
	ccm0: memory@10000000 {
		compatible = "zephyr,memory-region",
		             "st,stm32-ccm";         /* in zephyr/dts/arm/st/f3/stm32f334X8.dtsi:11 */
		reg = < 0x10000000 0x1000 >;         /* in zephyr/dts/arm/st/f3/stm32f334X8.dtsi:12 */
		zephyr,memory-region = "CCM";        /* in zephyr/dts/arm/st/f3/stm32f334X8.dtsi:13 */
	};

	/* node '/connector' defined in zephyr/boards/st/nucleo_f334r8/arduino_r3_connector.dtsi:10 */
	arduino_header: connector {
		compatible = "arduino-header-r3";          /* in zephyr/boards/st/nucleo_f334r8/arduino_r3_connector.dtsi:11 */
		#gpio-cells = < 0x2 >;                     /* in zephyr/boards/st/nucleo_f334r8/arduino_r3_connector.dtsi:12 */
		gpio-map-mask = < 0xffffffff 0xffffffc0 >; /* in zephyr/boards/st/nucleo_f334r8/arduino_r3_connector.dtsi:13 */
		gpio-map-pass-thru = < 0x0 0x3f >;         /* in zephyr/boards/st/nucleo_f334r8/arduino_r3_connector.dtsi:14 */
		gpio-map = < 0x0 0x0 &gpioa 0x0 0x0 >,
		           < 0x1 0x0 &gpioa 0x1 0x0 >,
		           < 0x2 0x0 &gpioa 0x4 0x0 >,
		           < 0x3 0x0 &gpiob 0x0 0x0 >,
		           < 0x4 0x0 &gpioc 0x1 0x0 >,
		           < 0x5 0x0 &gpioc 0x0 0x0 >,
		           < 0x6 0x0 &gpioa 0x3 0x0 >,
		           < 0x7 0x0 &gpioa 0x2 0x0 >,
		           < 0x8 0x0 &gpioa 0xa 0x0 >,
		           < 0x9 0x0 &gpiob 0x3 0x0 >,
		           < 0xa 0x0 &gpiob 0x5 0x0 >,
		           < 0xb 0x0 &gpiob 0x4 0x0 >,
		           < 0xc 0x0 &gpiob 0xa 0x0 >,
		           < 0xd 0x0 &gpioa 0x8 0x0 >,
		           < 0xe 0x0 &gpioa 0x9 0x0 >,
		           < 0xf 0x0 &gpioc 0x7 0x0 >,
		           < 0x10 0x0 &gpiob 0x6 0x0 >,
		           < 0x11 0x0 &gpioa 0x7 0x0 >,
		           < 0x12 0x0 &gpioa 0x6 0x0 >,
		           < 0x13 0x0 &gpioa 0x5 0x0 >,
		           < 0x14 0x0 &gpiob 0x9 0x0 >,
		           < 0x15 0x0 &gpiob 0x8 0x0 >;    /* in zephyr/boards/st/nucleo_f334r8/arduino_r3_connector.dtsi:15 */
	};

	/* node '/st-morpho-header' defined in zephyr/boards/st/nucleo_f334r8/st_morpho_connector.dtsi:10 */
	st_morpho_header: st-morpho-header {
		compatible = "st-morpho-header";        /* in zephyr/boards/st/nucleo_f334r8/st_morpho_connector.dtsi:11 */
		#gpio-cells = < 0x2 >;                  /* in zephyr/boards/st/nucleo_f334r8/st_morpho_connector.dtsi:12 */
		gpio-map-mask = < 0xff 0x0 >;           /* in zephyr/boards/st/nucleo_f334r8/st_morpho_connector.dtsi:13 */
		gpio-map-pass-thru = < 0x0 0x7f >;      /* in zephyr/boards/st/nucleo_f334r8/st_morpho_connector.dtsi:14 */
		gpio-map = < 0x0 0x0 &gpioc 0xa 0x0 >,
		           < 0x1 0x0 &gpioc 0xb 0x0 >,
		           < 0x2 0x0 &gpioc 0xc 0x0 >,
		           < 0x3 0x0 &gpiod 0x2 0x0 >,
		           < 0xc 0x0 &gpioa 0xd 0x0 >,
		           < 0xe 0x0 &gpioa 0xe 0x0 >,
		           < 0x10 0x0 &gpioa 0xf 0x0 >,
		           < 0x14 0x0 &gpiob 0x7 0x0 >,
		           < 0x16 0x0 &gpioc 0xd 0x0 >,
		           < 0x18 0x0 &gpioc 0xe 0x0 >,
		           < 0x1a 0x0 &gpioc 0xf 0x0 >,
		           < 0x1b 0x0 &gpioa 0x0 0x0 >,
		           < 0x1c 0x0 &gpiof 0x0 0x0 >,
		           < 0x1d 0x0 &gpioa 0x1 0x0 >,
		           < 0x1e 0x0 &gpiof 0x1 0x0 >,
		           < 0x1f 0x0 &gpioa 0x4 0x0 >,
		           < 0x21 0x0 &gpiob 0x0 0x0 >,
		           < 0x22 0x0 &gpioc 0x2 0x0 >,
		           < 0x23 0x0 &gpioc 0x1 0x0 >,
		           < 0x24 0x0 &gpioc 0x3 0x0 >,
		           < 0x25 0x0 &gpioc 0x0 0x0 >,
		           < 0x48 0x0 &gpioc 0x9 0x0 >,
		           < 0x49 0x0 &gpioc 0x8 0x0 >,
		           < 0x4a 0x0 &gpiob 0x8 0x0 >,
		           < 0x4b 0x0 &gpioc 0x6 0x0 >,
		           < 0x4c 0x0 &gpiob 0x9 0x0 >,
		           < 0x4d 0x0 &gpioc 0x5 0x0 >,
		           < 0x52 0x0 &gpioa 0x5 0x0 >,
		           < 0x53 0x0 &gpioa 0xc 0x0 >,
		           < 0x54 0x0 &gpioa 0x6 0x0 >,
		           < 0x55 0x0 &gpioa 0xb 0x0 >,
		           < 0x56 0x0 &gpioa 0x7 0x0 >,
		           < 0x57 0x0 &gpiob 0xc 0x0 >,
		           < 0x58 0x0 &gpiob 0x6 0x0 >,
		           < 0x59 0x0 &gpiob 0xb 0x0 >,
		           < 0x5a 0x0 &gpioc 0x7 0x0 >,
		           < 0x5c 0x0 &gpioa 0x9 0x0 >,
		           < 0x5d 0x0 &gpiob 0x2 0x0 >,
		           < 0x5e 0x0 &gpioa 0x8 0x0 >,
		           < 0x5f 0x0 &gpiob 0x1 0x0 >,
		           < 0x60 0x0 &gpiob 0xa 0x0 >,
		           < 0x61 0x0 &gpiob 0xf 0x0 >,
		           < 0x62 0x0 &gpiob 0x4 0x0 >,
		           < 0x63 0x0 &gpiob 0xe 0x0 >,
		           < 0x64 0x0 &gpiob 0x5 0x0 >,
		           < 0x65 0x0 &gpiob 0xd 0x0 >,
		           < 0x66 0x0 &gpiob 0x3 0x0 >,
		           < 0x68 0x0 &gpioa 0xa 0x0 >,
		           < 0x69 0x0 &gpioc 0x4 0x0 >,
		           < 0x6a 0x0 &gpioa 0x2 0x0 >,
		           < 0x6c 0x0 &gpioa 0x3 0x0 >; /* in zephyr/boards/st/nucleo_f334r8/st_morpho_connector.dtsi:15 */
	};

	/* node '/leds' defined in zephyr/boards/st/nucleo_f334r8/nucleo_f334r8.dts:25 */
	leds: leds {
		compatible = "gpio-leds"; /* in zephyr/boards/st/nucleo_f334r8/nucleo_f334r8.dts:26 */

		/* node '/leds/led_2' defined in zephyr/boards/st/nucleo_f334r8/nucleo_f334r8.dts:28 */
		green_led_2: led_2 {
			gpios = < &gpioa 0x5 0x0 >; /* in zephyr/boards/st/nucleo_f334r8/nucleo_f334r8.dts:29 */
			label = "User LD2";         /* in zephyr/boards/st/nucleo_f334r8/nucleo_f334r8.dts:30 */
		};
	};

	/* node '/gpio_keys' defined in zephyr/boards/st/nucleo_f334r8/nucleo_f334r8.dts:34 */
	gpio_keys {
		compatible = "gpio-keys"; /* in zephyr/boards/st/nucleo_f334r8/nucleo_f334r8.dts:35 */

		/* node '/gpio_keys/button' defined in zephyr/boards/st/nucleo_f334r8/nucleo_f334r8.dts:37 */
		user_button: button {
			label = "User";             /* in zephyr/boards/st/nucleo_f334r8/nucleo_f334r8.dts:38 */
			gpios = < &gpioc 0xd 0x1 >; /* in zephyr/boards/st/nucleo_f334r8/nucleo_f334r8.dts:39 */
			zephyr,code = < 0xb >;      /* in zephyr/boards/st/nucleo_f334r8/nucleo_f334r8.dts:40 */
		};
	};
};
